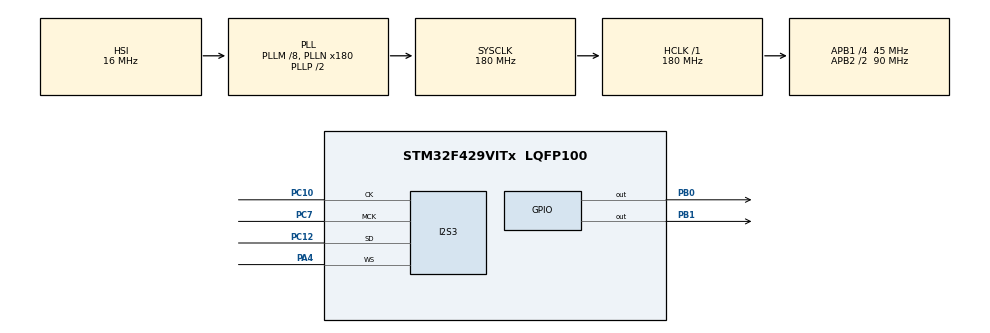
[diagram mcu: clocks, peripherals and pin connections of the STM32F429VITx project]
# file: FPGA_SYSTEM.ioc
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Dma.Request0=SPI3_TX
Dma.SPI3_TX.0.Direction=DMA_MEMORY_TO_PERIPH
Dma.SPI3_TX.0.FIFOMode=DMA_FIFOMODE_DISABLE
Dma.SPI3_TX.0.Instance=DMA1_Stream5
Dma.SPI3_TX.0.MemDataAlignment=DMA_MDATAALIGN_HALFWORD
Dma.SPI3_TX.0.MemInc=DMA_MINC_ENABLE
Dma.SPI3_TX.0.Mode=DMA_CIRCULAR
Dma.SPI3_TX.0.PeriphDataAlignment=DMA_PDATAALIGN_HALFWORD
Dma.SPI3_TX.0.PeriphInc=DMA_PINC_DISABLE
Dma.SPI3_TX.0.Priority=DMA_PRIORITY_HIGH
I2S3.AudioFreq=I2S_AUDIOFREQ_48K
I2S3.DataFormat=I2S_DATAFORMAT_16B_EXTENDED
I2S3.ErrorAudioFreq=-0.01 %
I2S3.FullDuplexMode=I2S_FULLDUPLEXMODE_DISABLE
I2S3.Instance=SPI$Index
I2S3.RealAudioFreq=47.991 KHz
I2S3.VirtualMode=I2S_MODE_MASTER
Mcu.Family=STM32F4
Mcu.Name=STM32F429VITx
Mcu.Package=LQFP100
NVIC.DMA1_Stream5_IRQn=true\:0\:0\:false\:false\:true\:false\:true
NVIC.PriorityGroup=NVIC_PRIORITYGROUP_4
PA13.Mode=JTAG_5_pins
PA13.Signal=SYS_JTMS-SWDIO
PA14.Mode=JTAG_5_pins
PA14.Signal=SYS_JTCK-SWCLK
PA15.Mode=JTAG_5_pins
PA15.Signal=SYS_JTDI
PA4.Mode=Half_Duplex_Master
PA4.Signal=I2S3_WS
PB0.Signal=GPIO_Output
PB1.Signal=GPIO_Output
PB3.Mode=JTAG_5_pins
PB3.Signal=SYS_JTDO-SWO
PB4.Mode=JTAG_5_pins
PB4.Signal=SYS_JTRST
PC10.Mode=Half_Duplex_Master
PC10.Signal=I2S3_CK
PC12.Mode=Half_Duplex_Master
PC12.Signal=I2S3_SD
PC7.Mode=Master_Clock_Activated
PC7.Signal=I2S3_MCK
ProjectManager.HeapSize=0x200
ProjectManager.StackSize=0x400
ProjectManager.TargetToolchain=STM32CubeIDE
RCC.48MHZClocksFreq_Value=90000000
RCC.AHBFreq_Value=180000000
RCC.APB1CLKDivider=RCC_HCLK_DIV4
RCC.APB1Freq_Value=45000000
RCC.APB1TimFreq_Value=90000000
RCC.APB2CLKDivider=RCC_HCLK_DIV2
RCC.APB2Freq_Value=90000000
RCC.APB2TimFreq_Value=180000000
RCC.CortexFreq_Value=180000000
RCC.HCLKFreq_Value=180000000
RCC.HSE_VALUE=25000000
RCC.HSI_VALUE=16000000
RCC.LSE_VALUE=32768
RCC.PLLI2SN=172
RCC.PLLI2SR=7
RCC.PLLM=8
RCC.PLLN=180
RCC.SYSCLKFreq_VALUE=180000000
RCC.SYSCLKSource=RCC_SYSCLKSOURCE_PLLCLK
RCC.VCOOutputFreq_Value=360000000
board=custom

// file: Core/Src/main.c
/* USER CODE BEGIN Header */
/**
  ******************************************************************************
  * @file           : main.c
  * @brief          : Main program body
  ******************************************************************************
  * @attention
  *
  * <h2><center>&copy; Copyright (c) 2021 STMicroelectronics.
  * All rights reserved.</center></h2>
  *
  * This software component is licensed by ST under BSD 3-Clause license,
  * the "License"; You may not use this file except in compliance with the
  * License. You may obtain a copy of the License at:
  *                        opensource.org/licenses/BSD-3-Clause
  *
  ******************************************************************************
  */
/* USER CODE END Header */
#include "main.h"

/* USER CODE BEGIN Includes */

#include "../Inc/MYLIB.h"

/* USER CODE END Includes */

I2S_HandleTypeDef hi2s3;
DMA_HandleTypeDef hdma_spi3_tx;

void SystemClock_Config(void);
static void MX_GPIO_Init(void);
static void MX_DMA_Init(void);
static void MX_I2S3_Init(void);

int main(void)
{

  /* MCU Configuration--------------------------------------------------------*/

  /* Reset of all peripherals, Initializes the Flash interface and the Systick. */
  HAL_Init();

  /* Configure the system clock */
  SystemClock_Config();

  /* Initialize all configured peripherals */
  MX_GPIO_Init();
  MX_DMA_Init();
  MX_I2S3_Init();
  /* USER CODE BEGIN 2 */

    uint32_t t = 0;

    music_set_info(1);
	i2s_dma_setting();
	tim2_init();
	tim3_init();
	tim7_init();
	GPIOB->ODR |= GPIO_ODR_OD0_Msk;
	t = get_time();

  /* USER CODE END 2 */

  /* Infinite loop */
  /* USER CODE BEGIN WHILE */
  while (1)
  {
	  if (true == comparater_time(&t, TM_1SEC_COUNT, 'S')) {
		  GPIOB->ODR ^= GPIO_ODR_OD0_Msk;
		  GPIOB->ODR ^= GPIO_ODR_OD1_Msk;
		  t = get_time();
	  }
	  music_update();
    /* USER CODE END WHILE */

  }
}

void SystemClock_Config(void)
{
  RCC_OscInitTypeDef RCC_OscInitStruct = {0};
  RCC_ClkInitTypeDef RCC_ClkInitStruct = {0};
  RCC_PeriphCLKInitTypeDef PeriphClkInitStruct = {0};

  /** Configure the main internal regulator output voltage
  */
  __HAL_RCC_PWR_CLK_ENABLE();
  __HAL_PWR_VOLTAGESCALING_CONFIG(PWR_REGULATOR_VOLTAGE_SCALE1);
  /** Initializes the RCC Oscillators according to the specified parameters
  * in the RCC_OscInitTypeDef structure.
  */
  RCC_OscInitStruct.OscillatorType = RCC_OSCILLATORTYPE_HSI;
  RCC_OscInitStruct.HSIState = RCC_HSI_ON;
  RCC_OscInitStruct.HSICalibrationValue = RCC_HSICALIBRATION_DEFAULT;
  RCC_OscInitStruct.PLL.PLLState = RCC_PLL_ON;
  RCC_OscInitStruct.PLL.PLLSource = RCC_PLLSOURCE_HSI;
  RCC_OscInitStruct.PLL.PLLM = 8;
  RCC_OscInitStruct.PLL.PLLN = 180;
  RCC_OscInitStruct.PLL.PLLP = RCC_PLLP_DIV2;
  RCC_OscInitStruct.PLL.PLLQ = 4;
  if (HAL_RCC_OscConfig(&RCC_OscInitStruct) != HAL_OK)
  {
    Error_Handler();
  }
  /** Activate the Over-Drive mode
  */
  if (HAL_PWREx_EnableOverDrive() != HAL_OK)
  {
    Error_Handler();
  }
  /** Initializes the CPU, AHB and APB buses clocks
  */
  RCC_ClkInitStruct.ClockType = RCC_CLOCKTYPE_HCLK|RCC_CLOCKTYPE_SYSCLK
                              |RCC_CLOCKTYPE_PCLK1|RCC_CLOCKTYPE_PCLK2;
  RCC_ClkInitStruct.SYSCLKSource = RCC_SYSCLKSOURCE_PLLCLK;
  RCC_ClkInitStruct.AHBCLKDivider = RCC_SYSCLK_DIV1;
  RCC_ClkInitStruct.APB1CLKDivider = RCC_HCLK_DIV4;
  RCC_ClkInitStruct.APB2CLKDivider = RCC_HCLK_DIV2;

  if (HAL_RCC_ClockConfig(&RCC_ClkInitStruct, FLASH_LATENCY_5) != HAL_OK)
  {
    Error_Handler();
  }
  PeriphClkInitStruct.PeriphClockSelection = RCC_PERIPHCLK_I2S;
  PeriphClkInitStruct.PLLI2S.PLLI2SN = 172;
  PeriphClkInitStruct.PLLI2S.PLLI2SR = 7;
  if (HAL_RCCEx_PeriphCLKConfig(&PeriphClkInitStruct) != HAL_OK)
  {
    Error_Handler();
  }
}

static void MX_I2S3_Init(void)
{

  hi2s3.Instance = SPI3;
  hi2s3.Init.Mode = I2S_MODE_MASTER_TX;
  hi2s3.Init.Standard = I2S_STANDARD_PHILIPS;
  hi2s3.Init.DataFormat = I2S_DATAFORMAT_16B_EXTENDED;
  hi2s3.Init.MCLKOutput = I2S_MCLKOUTPUT_ENABLE;
  hi2s3.Init.AudioFreq = I2S_AUDIOFREQ_48K;
  hi2s3.Init.CPOL = I2S_CPOL_LOW;
  hi2s3.Init.ClockSource = I2S_CLOCK_PLL;
  hi2s3.Init.FullDuplexMode = I2S_FULLDUPLEXMODE_DISABLE;
  if (HAL_I2S_Init(&hi2s3) != HAL_OK)
  {
    Error_Handler();
  }

}

static void MX_DMA_Init(void)
{

  /* DMA controller clock enable */
  __HAL_RCC_DMA1_CLK_ENABLE();

  /* DMA interrupt init */
  /* DMA1_Stream5_IRQn interrupt configuration */
  HAL_NVIC_SetPriority(DMA1_Stream5_IRQn, 0, 0);
  HAL_NVIC_EnableIRQ(DMA1_Stream5_IRQn);

}

static void MX_GPIO_Init(void)
{
  GPIO_InitTypeDef GPIO_InitStruct = {0};

  /* GPIO Ports Clock Enable */
  __HAL_RCC_GPIOA_CLK_ENABLE();
  __HAL_RCC_GPIOB_CLK_ENABLE();
  __HAL_RCC_GPIOC_CLK_ENABLE();

  /*Configure GPIO pin Output Level */
  HAL_GPIO_WritePin(GPIOB, GPIO_PIN_0|GPIO_PIN_1, GPIO_PIN_RESET);

  /*Configure GPIO pins : PB0 PB1 */
  GPIO_InitStruct.Pin = GPIO_PIN_0|GPIO_PIN_1;
  GPIO_InitStruct.Mode = GPIO_MODE_OUTPUT_PP;
  GPIO_InitStruct.Pull = GPIO_NOPULL;
  GPIO_InitStruct.Speed = GPIO_SPEED_FREQ_LOW;
  HAL_GPIO_Init(GPIOB, &GPIO_InitStruct);

}

void Error_Handler(void)
{
  __disable_irq();
  while (1)
  {
  }
}

/************************ (C) COPYRIGHT STMicroelectronics *****END OF FILE****/
